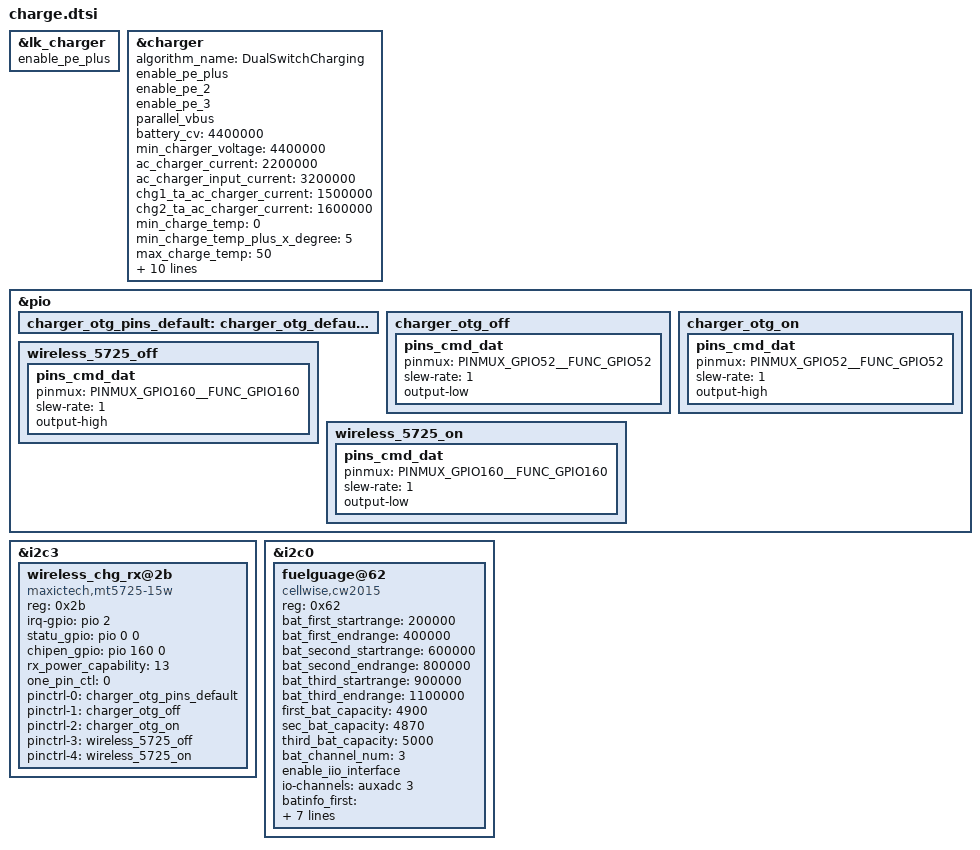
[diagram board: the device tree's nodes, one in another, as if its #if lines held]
/*prize-sunshuai-20200901, modify for charge start*/
&lk_charger {
    enable_pe_plus;
};

&charger {
	algorithm_name = "DualSwitchCharging";
	enable_pe_plus;
	enable_pe_2;
	enable_pe_3;
	parallel_vbus;
	battery_cv = <4400000>;
	min_charger_voltage = <4400000>;

	ac_charger_current = <2200000>;
	ac_charger_input_current = <3200000>;

	/* dual charger */
	chg1_ta_ac_charger_current = <1500000>;
	chg2_ta_ac_charger_current = <1600000>;

	min_charge_temp = <0>;
	min_charge_temp_plus_x_degree = <5>;
	max_charge_temp = <50>;
	max_charge_temp_minus_x_degree = <48>;

#if defined(CONFIG_PRIZE_CHARGE_CURRENT_CTRL_GIGAST)
	  start_step1_temp = <(0)>;
	  step1_max_current = <1320000>;
	  start_step2_temp = <15>;
	  start_step3_temp = <45>;
	  step2_max_current = <4400000>;
	  start_step4_temp = <50>;
	  step3_vot1_current = <1320000>;
	  step3_vot2_current = <840000>;
      temp_stp3_cv_voltage = <4100>;
#endif
};
/*prize-sunshuai-20200901, modify for charge end*/




//prize add by lipengpeng wireless  start
&pio {
        charger_otg_pins_default: charger_otg_default {
        };
        charger_otg_off:  charger_otg_off {
            pins_cmd_dat {
                        pinmux = <PINMUX_GPIO52__FUNC_GPIO52>;
                        slew-rate = <1>;
                        output-low;
                };
        };
        charger_otg_on:  charger_otg_on {
            pins_cmd_dat {
                        pinmux = <PINMUX_GPIO52__FUNC_GPIO52>;
                        slew-rate = <1>;
                        output-high;
                };
        };
      wireless_5725_off:  wireless_5725_off {
            pins_cmd_dat {
                        pinmux = <PINMUX_GPIO160__FUNC_GPIO160>;
                        slew-rate = <1>;
                        output-high;
                };
        };
        wireless_5725_on:  wireless_5725_on {
            pins_cmd_dat {
                        pinmux = <PINMUX_GPIO160__FUNC_GPIO160>;
                        slew-rate = <1>;
                        output-low;
                };
        };
};
&i2c3 {
	wireless_chg_rx@2b {
		compatible = "maxictech,mt5725-15w";
		reg = <0x2b>;
		irq-gpio = <&pio 2 0>;//W_CHARGE_INT
		//trxset_gpio = <&pio 88 0>;//DC_EN
		//otgen_gpio = <&pio 87 0>;
		statu_gpio = <&pio 0 0>;//WRX_EN
		chipen_gpio = <&pio 160 0>;//CHARGE_EN
		//rx_power_capability = <10>;
		//one_pin_ctl = <1>;
		rx_power_capability = <13>;
	   one_pin_ctl = <0>;
	   pinctrl-names = "default", "charger_otg_off", "charger_otg_on",
				 "wireless_5725_off", "wireless_5725_on";
	   pinctrl-0 = <&charger_otg_pins_default>;
	   pinctrl-1 = <&charger_otg_off>;//WPC_OTG_EN
	   pinctrl-2 = <&charger_otg_on>;//WPC_OTG_EN
	   pinctrl-3 = <&wireless_5725_off>;//WPC_OTG_EN2
	   pinctrl-4 = <&wireless_5725_on>;//WPC_OTG_EN2
	};
};
//prize add by lipengpeng wireless  end 
/* prize sunshuai 20200427 add for 5725 15W wireless charge end */

/*
 * Copyright (C) 2019 prize sunshuai.
 * get cw2015 battery info from dts
 */
&i2c0 {
	fuelguage@62 {
		compatible = "cellwise,cw2015";
		reg = <0x62>;
/* prize-add-sunshuai-2015 Multi-Battery Solution-20200222-start */
#ifdef CONFIG_MTK_CW2015_BATTERY_ID_AUXADC
		bat_first_startrange = <200000>;
		bat_first_endrange = <400000>;
		bat_second_startrange = <600000>;
		bat_second_endrange = <800000>;
		bat_third_startrange = <900000>;
		bat_third_endrange = <1100000>;
		first_bat_capacity = <4900>;
		sec_bat_capacity = <4870>;
		third_bat_capacity = <5000>;
		bat_channel_num = <3>;//when set enable_iio_interface, it is only used in LK phase; When not using enable_iio_interface,lk and kernel use
/* prize-add-sunshuai-2015 Multi-Battery Solution for iio interface 20200904-start */
#if defined(CONFIG_MACH_MT6768)
#if defined(CONFIG_MEDIATEK_MT6577_AUXADC)
		enable_iio_interface;//Use of MTK IIO new architecture
		io-channels = <&auxadc 3>;
		io-channel-names = "thermistor-ch3";
#endif
#endif
/* prize-add-sunshuai-2015 Multi-Battery Solution for iio interface 20200904-end */
#endif
/* prize-add-sunshuai-2015 Multi-Battery Solution-20200222-end */

/* prize-add-sunshuai-2015 Multi-Battery Solution-20200222-start */
#ifdef CONFIG_MTK_CW2015_BATTERY_ID_AUXADC
        batinfo_first = /bits/ 8 <0x18 0x0A 0x62 0x66 0x68 0x68 0x67 0x67 0x63 0x5D 0x67 0x59 0x6D 0x53 0x47 0x41
					0x39 0x31 0x2C 0x29 0x2D 0x3A 0x45 0x4B 0x1A 0x64 0x0B 0x85 0x1D 0x3B 0x43 0x51
					0x65 0x68 0x68 0x6D 0x40 0x1C 0x6D 0x55 0x0B 0x1C 0x37 0x62 0x82 0x94 0x99 0x0E
					0x23 0x76 0x96 0xA4 0x80 0x90 0xBB 0xCB 0x2F 0x00 0x64 0xA5 0xB5 0x0E 0x09 0x29>;
	    batinfo_second = /bits/ 8 <0x18 0x0A 0x6B 0x6B 0x6B 0x6B 0x68 0x67 0x60 0x68 0x5A 0x59 0x63 0x5A 0x48 0x3F
					0x36 0x2F 0x29 0x24 0x28 0x30 0x41 0x4F 0x28 0x4A 0x0B 0x85 0x34 0x55 0x56 0x6F
					0x82 0x7F 0x80 0x81 0x3E 0x19 0x5D 0x57 0x0B 0x36 0x29 0x5A 0x83 0x94 0x99 0x0D
					0x29 0x7A 0x96 0xA8 0x80 0x95 0xAA 0xCB 0x2F 0x00 0x64 0xA5 0xB5 0x0E 0x08 0xB9>;
	   batinfo_third = /bits/ 8 <0x18 0x14 0x5F 0x69 0x6F 0x6B 0x6A 0x68 0x62 0x65 0x61 0x59 0x64 0x59 0x49 0x41
                    0x37 0x31 0x27 0x21 0x27 0x35 0x41 0x4F 0x21 0x46 0x0B 0x85 0x28 0x48 0x51 0x6C
                    0x81 0x7E 0x7E 0x7E 0x3E 0x1B 0x5C 0x46 0x0E 0x20 0x52 0x87 0x8F 0x91 0x94 0x52
                    0x82 0x8C 0x92 0x96 0x95 0xA6 0xC3 0xCB 0x2F 0x7D 0x64 0xA5 0xB5 0x0E 0x08 0x69>;
	    batinfo_default = /bits/ 8 <0x18 0x0A 0x62 0x66 0x68 0x68 0x67 0x67 0x63 0x5D 0x67 0x59 0x6D 0x53 0x47 0x41
					0x39 0x31 0x2C 0x29 0x2D 0x3A 0x45 0x4B 0x1A 0x64 0x0B 0x85 0x1D 0x3B 0x43 0x51
					0x65 0x68 0x68 0x6D 0x40 0x1C 0x6D 0x55 0x0B 0x1C 0x37 0x62 0x82 0x94 0x99 0x0E
					0x23 0x76 0x96 0xA4 0x80 0x90 0xBB 0xCB 0x2F 0x00 0x64 0xA5 0xB5 0x0E 0x09 0x29>;
#else
		batinfo =  /bits/ 8 <0x18 0x0A 0x63 0x67 0x6A 0x69 0x68 0x67 0x64 0x5F 0x6E 0x52 0x5B 0x56 0x4A 0x43
					0x3F 0x36 0x2D 0x23 0x25 0x34 0x44 0x4B 0x20 0x4F 0x0B 0x85 0x18 0x30 0x3D 0x4C
					0x55 0x58 0x58 0x5B 0x3E 0x1B 0x69 0x52 0x0B 0x27 0x27 0x53 0x7E 0x96 0xA1 0x13
					0x39 0x7C 0x96 0x98 0x80 0x9D 0xDC 0xCB 0x2F 0x00 0x64 0xA5 0xB5 0x0E 0x0A 0x01>;
#endif
/* prize-add-sunshuai-2015 Multi-Battery Solution-20200222-end */
	};
};


